# ESP32-H4 register map
Vendor: ESPRESSIF SYSTEMS (SHANGHAI) CO., LTD.; Series: ESP32 H-Series; File version: 1
CPU: RV32IMAC r0p0, little endian, no MPU, no FPU, 0 interrupt priority bits
Address unit: 32 bits
Registers are 32-bit, read-write, reset 0x0 unless marked. A register's access mark holds for its fields unless they carry their own. Offsets are from the block's base; [hi:lo] are bit positions; {n}, {i} and the like mark numbered series; <NAME> marks a mode.

## USB0 (part 3 of 4) — USB OTG (On-The-Go)
Base 0x60040000
Same registers: USB1 0x6007F000
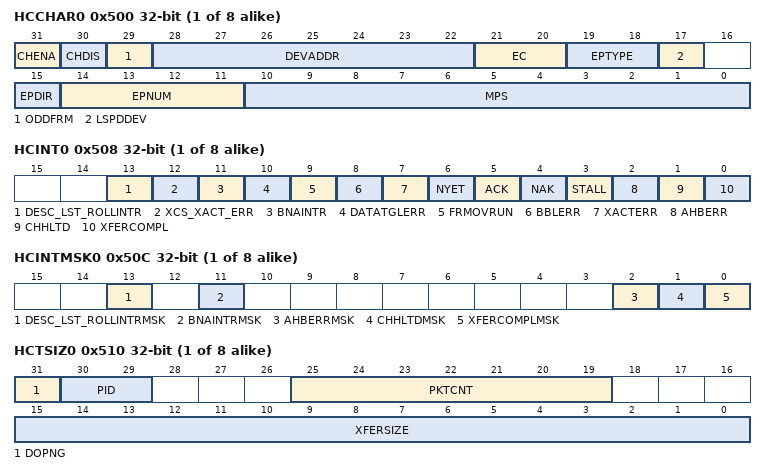
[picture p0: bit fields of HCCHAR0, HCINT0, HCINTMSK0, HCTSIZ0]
{0x500+0x20*i} HCCHAR{i} (i=0..7) — Host Channel {i} Characteristics Register
  [31] CHENA — Channel Enable (ChEna) When Scatter/Gather mode is enabled - 1'b0: Indicates that the descriptor structure is not yet ready. - 1'b1: Indicates that the descriptor structure and data buffer with data is setup and this channel can access the descriptor. When Scatter/Gather mode is disabled This field is set by the application and cleared by the OTG host. - 1'b0: Channel disabled - 1'b1: Channel enabled
  [30] CHDIS — Channel Disable (ChDis) The application sets this bit to stop transmitting/receiving data on a channel, even before the transfer for that channel is complete. The application must wait for the Channel Disabled interrupt before treating the channel as disabled.
  [29] ODDFRM — Odd Frame (OddFrm) This field is set (reset) by the application to indicate that the OTG host must perform a transfer in an odd (micro)Frame. This field is applicable for only periodic (isochronous and interrupt) transactions. - 1'b0: Even (micro)Frame - 1'b1: Odd (micro)Frame
  [28:22] DEVADDR — Device Address (DevAddr) This field selects the specific device serving as the data source or sink.
  [21:20] EC — Multi Count (MC) / Error Count (EC) When the Split Enable bit of the Host Channel-n Split Control register (HCSPLTn.SpltEna) is reset (1'b0), this field indicates to the host the number of transactions that must be executed per microframe for this periodic endpoint. For non periodic transfers, this field is used only in DMA mode, and specifies the number packets to be fetched for this channel before the internal DMA engine changes arbitration. - 2'b00: Reserved This field yields undefined results. - 2'b01: 1 transaction - 2'b10: 2 transactions to be issued for this endpoint per microframe - 2'b11: 3 transactions to be issued for this endpoint per microframe When HCSPLTn.SpltEna is Set (1'b1), this field indicates the number of immediate retries to be performed for a periodic split transactions on transaction errors. This field must be Set to at least 2'b01.
  [19:18] EPTYPE — Endpoint Type (EPType) Indicates the transfer type selected. - 2'b00: Control - 2'b01: Isochronous - 2'b10: Bulk - 2'b11: Interrupt
  [17] LSPDDEV — Low-Speed Device (LSpdDev) This field is Set by the application to indicate that this channel is communicating to a low-speed device. The application must program this bit when a low speed device is connected to the host through an FS HUB. The DWC_otg Host core uses this field to drive the XCVR_SELECT signal to 2'b11 while communicating to the LS Device through the FS hub. Note: In a peer to peer setup, the DWC_otg Host core ignores this bit even if it is set by the application software.
  [15] EPDIR — Endpoint Direction (EPDir) Indicates whether the transaction is IN or OUT. - 1'b0: OUT - 1'b1: IN
  [14:11] EPNUM — Endpoint Number (EPNum) Indicates the endpoint number on the device serving as the data source or sink.
  [10:0] MPS — Maximum Packet Size (MPS) Indicates the maximum packet size of the associated endpoint.
{0x508+0x20*i} HCINT{i} (i=0..7) — Host Channel $i Interrupt Register This register indicates the status of a channel with respect to USB- and AHB-related events. It is shown in the Interrupt Hierarchy figure in the databook. The application must read this register when the Host Channels Interrupt bit of the Core Interrupt register (GINTSTS.HChInt) is set. Before the application can read this register, it must first read the Host All Channels Interrupt (HAINT) register to get the exact channel number for the Host Channel-n Interrupt register. The application must clear the appropriate bit in this register to clear the corresponding bits in the HAINT and GINTSTS registers.
  [13] DESC_LST_ROLLINTR — Descriptor rollover interrupt (DESC_LST_ROLLIntr) This bit is valid only when Scatter/Gather DMA mode is enabled. The core sets this bit when the corresponding channel's descriptor list rolls over. For non Scatter/Gather DMA mode, this bit is reserved.
  [12] XCS_XACT_ERR — Excessive Transaction Error (XCS_XACT_ERR) This bit is valid only when Scatter/Gather DMA mode is enabled. The core sets this bit when 3 consecutive transaction errors occurred on the USB bus. XCS_XACT_ERR will not be generated for Isochronous channels. For non Scatter/Gather DMA mode, this bit is reserved.
  [11] BNAINTR — BNA (Buffer Not Available) Interrupt (BNAIntr) This bit is valid only when Scatter/Gather DMA mode is enabled. The core generates this interrupt when the descriptor accessed is not ready for the Core to process. BNA will not be generated for Isochronous channels. For non Scatter/Gather DMA mode, this bit is reserved.
  [10] DATATGLERR — Data Toggle Error (DataTglErr).This bit can be set only by the core and the application should write 1 to clear it.In Scatter/Gather DMA mode, the interrupt due to this bit is masked in the core.
  [9] FRMOVRUN — Frame Overrun (FrmOvrun). In Scatter/Gather DMA mode, the interrupt due to this bit is masked in the core. This bit can be set only by the core and the application should write 1 to clear it.
  [8] BBLERR — Babble Error (BblErr) In Scatter/Gather DMA mode, the interrupt due to this bit is masked in the core. This bit can be set only by the core and the application should write 1 to clear it.
  [7] XACTERR — Transaction Error (XactErr) Indicates one of the following errors occurred on the USB. - CRC check failure - Timeout - Bit stuff error - False EOP In Scatter/Gather DMA mode, the interrupt due to this bit is masked in the core.This bit can be set only by the core and the application should write 1 to clear it.
  [6] NYET — NYET Response Received Interrupt (NYET) In Scatter/Gather DMA mode, the interrupt due to this bit is masked in the core.This bit can be set only by the core and the application should write 1 to clear it.
  [5] ACK — ACK Response Received/Transmitted Interrupt (ACK) In Scatter/Gather DMA mode, the interrupt due to this bit is masked in the core.This bit can be set only by the core and the application should write 1 to clear it.
  [4] NAK — NAK Response Received Interrupt (NAK) In Scatter/Gather DMA mode, the interrupt due to this bit is masked in the core.This bit can be set only by the core and the application should write 1 to clear it.
  [3] STALL — STALL Response Received Interrupt (STALL) In Scatter/Gather DMA mode, the interrupt due to this bit is masked in the core.This bit can be set only by the core and the application should write 1 to clear it.
  [2] AHBERR — AHB Error (AHBErr) This is generated only in Internal DMA mode when there is an AHB error during AHB read/write. The application can read the corresponding channel's DMA address register to get the error address.
  [1] CHHLTD — Channel Halted (ChHltd) In non Scatter/Gather DMA mode, it indicates the transfer completed abnormally either because of any USB transaction error or in response to disable request by the application or because of a completed transfer. In Scatter/gather DMA mode, this indicates that transfer completed due to any of the following - EOL being set in descriptor - AHB error - Excessive transaction errors - Babble - Stall
  [0] XFERCOMPL — Transfer Completed (XferCompl) Transfer completed normally without any errors.This bit can be set only by the core and the application should write 1 to clear it. - For Scatter/Gather DMA mode, it indicates that current descriptor processing got completed with IOC bit set in its descriptor. - In non Scatter/Gather DMA mode, it indicates that Transfer completed normally without any errors.
{0x50C+0x20*i} HCINTMSK{i} (i=0..7) — Host Channel $i Interrupt Mask Register This register reflects the mask for each channel status described in the previous section.
  [13] DESC_LST_ROLLINTRMSK — Descriptor List rollover interrupt Mask register(DESC_LST_ROLLIntrMsk) This bit is valid only when Scatter/Gather DMA mode is enabled.
  [11] BNAINTRMSK — BNA (Buffer Not Available) Interrupt mask register (BNAIntrMsk) This bit is valid only when Scatter/Gather DMA mode is enabled.
  [2] AHBERRMSK — AHB Error Mask (AHBErrMsk) In scatter/gather DMA mode for host, interrupts will not be generated due to the corresponding bits set in HCINTn.
  [1] CHHLTDMSK — Channel Halted Mask (ChHltdMsk)
  [0] XFERCOMPLMSK — Transfer Completed Mask (XferComplMsk)
{0x510+0x20*i} HCTSIZ{i} (i=0..7) — Host Channel {i} Transfer Size Register
  [31] DOPNG — Do Ping (DoPng) This bit is used only for OUT transfers. Setting this field to 1 directs the host to do PING protocol. Note: Do not set this bit for IN transfers. If this bit is set for for IN transfers it disables the channel.
  [30:29] PID — PID (Pid) The application programs this field with the type of PID to use for the initial transaction. The host maintains this field for the rest of the transfer. - 2'b00: DATA0 - 2'b01: DATA2 - 2'b10: DATA1 - 2'b11: MDATA (non-control)/SETUP (control)
  [25:19] PKTCNT — Packet Count (PktCnt) This field is programmed by the application with the expected number of packets to be transmitted (OUT) or received (IN). The host decrements this count on every successful transmission or reception of an OUT/IN packet. Once this count reaches zero, the application is interrupted to indicate normal completion. The width of this counter is specified as Width of Packet Counters during coreConsultant configuration (parameter OTG_PACKET_COUNT_WIDTH).
  [15:0] XFERSIZE — Transfer Size (XferSize) For an OUT, this field is the number of data bytes the host sends during the transfer. For an IN, this field is the buffer size that the application has Reserved for the transfer. The application is expected to program this field as an integer multiple of the maximum packet size for IN transactions (periodic and non-periodic). The width of this counter is specified as Width of Transfer Size Counters during coreConsultant configuration (parameter OTG_TRANS_COUNT_WIDTH).
{0x514+0x20*i} HCDMA{i} (i=0..7) — Host Channel $i DMA Address Register This register is used by the OTG host in the internal DMA mode to maintain the current buffer pointer for IN/OUT transactions. The starting DMA address must be DWORD-aligned.
  [31:0] DMAADDR — In Buffer DMA Mode: [31:0]: DMA Address (DMAAddr) This field holds the start address in the external memory from which the data for the endpoint must be fetched or to which it must be stored. This register is incremented on every AHB transaction. Reset: X if not programmed as the register is in SPRAM. In Scatter-Gather DMA (DescDMA) Mode for Non-Isochronous: [31:9]: DMA Address (DMAAddr) The start address must be 512-bytes aligned. This field holds the start address of the 512 bytes page. The first descriptor in the list should be located in this address. The first descriptor may be or may not be ready. The core starts processing the list from the CTD value. [8:3]: Current Transfer Desc(CTD) This value is in terms of number of descriptors. The values can be from 0 to 63. - 0 - 1 descriptor. - 63 - 64 descriptors. This field indicates the current descriptor processed in the list. This field is updated both by application and the core. For example, if the application enables the channel after programming CTD=5, then the core will start processing the sixth descriptor. The address is obtained by adding a value of (8bytes*5=) 40(decimal) to DMAAddr. Reset: 6'h0 [2:0]: Reserved In Scatter-Gather DMA (DescDMA) Mode for Isochronous: [31:N]: DMA Address (DMAAddr) The start address must be 512-bytes aligned. This field holds the address of the 2*(nTD+1) bytes of locations in which the isochronous descriptors are present where N is based on nTD as follows: - [31:N]: Base Address - [N-1:3]: Offset - [2:0]: 000 For HS ISOC, if nTD is, - 7, N=6 - 15, N=7 - 31, N=8 - 63, N=9 - 127, N=10 - 255, N=11 For FS ISOC, if nTD is, - 1, N=4 - 3, N=5 - 7, N=6 - 15, N=7 - 31, N=8 - 63, N=9 [N-1:3]: Current Transfer Desc(CTD) CTD for isochronous is based on the current frame/(micro)frame value. Need to be set to zero by application. Reset: (N+1:3)'h0 [2:0]: Reserved
{0x51C+0x20*i} HCDMAB{i} ro (i=0..7) — Host Channel $i DMA Buffer Address Register This register is present only in case of Scatter/Gather DMA. It is implemented in RAM instead of flop-based implementation. This register holds the current buffer address.
  [31:0] HCDMAB — Holds the current buffer address. This register is updated as and when the data transfer for the corresponding end point is in progress. This register is present only in Scatter/Gather DMA mode. Otherwise this field is reserved.
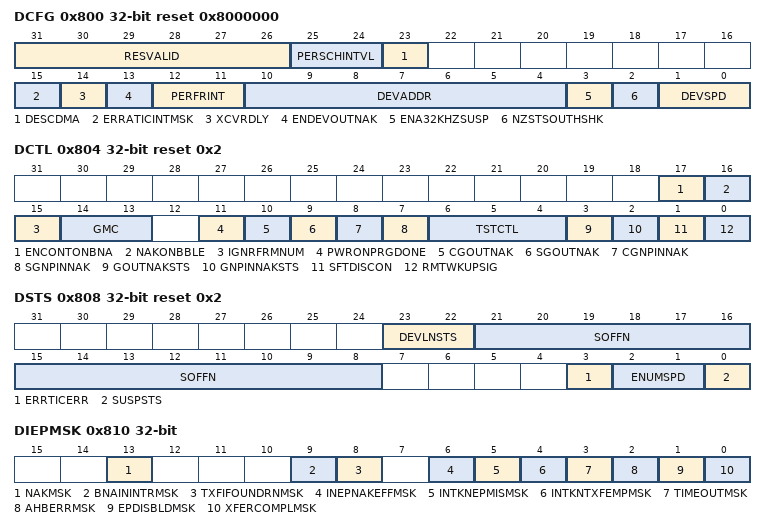
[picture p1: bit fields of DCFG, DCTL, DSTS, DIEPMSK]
0x800 DCFG reset 0x8000000 — Device Configuration Register This register configures the core in Device mode after power-on or after certain control commands or enumeration. Do not make changes to this register after initial programming.
  [31:26] RESVALID — Resume Validation Period (ResValid) This field is effective only when DCFG.Ena32KHzSusp is set. It controls the resume period when the core resumes from suspend. The core counts for ResValid number of clock cycles to detect a valid resume when this bit is set
  [25:24] PERSCHINTVL — Periodic Scheduling Interval (PerSchIntvl) PerSchIntvl must be programmed for Scatter/Gather DMA mode. This field specifies the amount of time the Internal DMA engine must allocate for fetching periodic IN endpoint data. Based on the number of periodic endpoints, this value must be specified as 25,50 or 75% of (micro)Frame. - When any periodic endpoints are active, the internal DMA engine allocates the specified amount of time in fetching periodic IN endpoint data . - When no periodic endpoints are active, Then the internal DMA engine services non-periodic endpoints, ignoring this field. - After the specified time within a (micro)Frame, the DMA switches to fetching for non-periodic endpoints. -- 2'b00: 25% of (micro)Frame. -- 2'b01: 50% of (micro)Frame. -- 2'b10: 75% of (micro)Frame. -- 2'b11: Reserved. Reset: 2'b00
  [23] DESCDMA — Enable Scatter/gather DMA in device mode (DescDMA). When the Scatter/Gather DMA option selected during configuration of the RTL, the application can Set this bit during initialization to enable the Scatter/Gather DMA operation. Note: This bit must be modified only once after a reset. The following combinations are available for programming: - GAHBCFG.DMAEn=0,DCFG.DescDMA=0 => Slave mode - GAHBCFG.DMAEn=0,DCFG.DescDMA=1 => Invalid - GAHBCFG.DMAEn=1,DCFG.DescDMA=0 => Buffered DMA mode - GAHBCFG.DMAEn=1,DCFG.DescDMA=1 => Scatter/Gather DMA mode
  [15] ERRATICINTMSK — Erratic Error Interrupt Mask
  [14] XCVRDLY — XCVRDLY Enables or disables delay between xcvr_sel and txvalid during device chirp
  [13] ENDEVOUTNAK — Enable Device OUT NAK (EnDevOutNak) This bit enables setting NAK for Bulk OUT endpoints after the transfer is completed for Device mode Descriptor DMA - 1'b0 : The core does not set NAK after Bulk OUT transfer complete - 1'b1 : The core sets NAK after Bulk OUT transfer complete It bit is one time programmable after reset like any other DCFG register bits.
  [12:11] PERFRINT — Periodic Frame Interval (PerFrInt) Indicates the time within a (micro)Frame at which the application must be notified using the End Of Periodic Frame Interrupt. This can be used to determine If all the isochronous traffic for that (micro)Frame is complete. - 2'b00: 80% of the (micro)Frame interval - 2'b01: 85% of the (micro)Frame interval - 2'b10: 90% of the (micro)Frame interval - 2'b11: 95% of the (micro)Frame interval
  [10:4] DEVADDR — Device Address (DevAddr) The application must program this field after every SetAddress control command.
  [3] ENA32KHZSUSP — Enable 32 KHz Suspend mode (Ena32KHzSusp) This bit can be set only if FS PHY interface is selected. Otherwise, this bit needs to be set to zero. If FS PHY interface is chosen and this bit is set, the PHY clock during Suspend must be switched from 48 MHz to 32 KHz.
  [2] NZSTSOUTHSHK — Non-Zero-Length Status OUT Handshake (NZStsOUTHShk) The application can use this field to select the handshake the core sends on receiving a nonzero-length data packet during the OUT transaction of a control transfer's Status stage. - 1'b1: Send a STALL handshake on a nonzero-length status OUT transaction and do not send the received OUT packet to the application. - 1'b0: Send the received OUT packet to the application (zerolength or nonzero-length) and send a handshake based on the NAK and STALL bits for the endpoint in the Device Endpoint Control register.
  [1:0] DEVSPD — Device Speed (DevSpd) Indicates the speed at which the application requires the core to enumerate, or the maximum speed the application can support. However, the actual bus speed is determined only after the connect sequence is completed, and is based on the speed of the USB host to which the core is connected.
0x804 DCTL access per field reset 0x2 — Device Control Register
  [17] ENCONTONBNA rw — Enable Continue on BNA (EnContOnBNA) This bit enables the core to continue on BNA for Bulk OUT endpoints. With this feature enabled, when a Bulk OUT or INTR OUT endpoint receives a BNA interrupt the core starts processing the descriptor that caused the BNA interrupt after the endpoint re-enables the endpoint. - 1'b0: After receiving BNA interrupt,the core disables the endpoint. When the endpoint is re-enabled by the application,the core starts processing from the DOEPDMA descriptor. - 1'b1: After receiving BNA interrupt, the core disables the endpoint. When the endpoint is re-enabled by the application, the core starts processing from the descriptor that received the BNA interrupt. This bit is valid only when OTG_EN_DESC_DMA == 1'b1. It is a one-time programmable after reset bit like any other DCTL register bits.
  [16] NAKONBBLE rw — NAK on Babble Error (NakOnBble) Set NAK automatically on babble (NakOnBble). The core sets NAK automatically for the endpoint on which babble is received.
  [15] IGNRFRMNUM rw — Ignore Frame Number Feature for Isochronous Endpoints (IgnrFrmNum) This field is also used to control the Periodic Transfer Interrupt (PTI) feature. Note: Do not program IgnrFrmNum bit to 1'b1 when the core is operating in threshold mode. Slave Mode (GAHBCFG.DMAEn=0): This bit is not valid in Slave mode and should not be programmed to 1. Scatter/Gather DMA Mode (GAHBCFG.DMAEn=1,DCFG.DescDMA=1): Note: When Scatter/Gather DMA mode is enabled this feature is not applicable to High Speed, High bandwidth transfers. When this bit is enabled, there must be only one packet per descriptor. - 0: The core transmits the packets only in the frame number in which they are intended to be transmitted. - 1: The core ignores the frame number, sending packets immediately as the packets are ready. In Scatter/Gather DMA mode, if this bit is enabled, the packets are not flushed when a ISOC IN token is received for an elapsed frame. Non-Scatter/Gather DMA Mode, that is, Buffer DMA Mode (GAHBCFG.DMAEn=1,DCFG.DescDMA=0): When Scatter/Gather DMA mode is disabled, this field is used by the application to enable Periodic Transfer Interrupt (PTI) Mode. The application can program Periodic Endpoint transfers for multiple (micro)Frames. - 0: Periodic Transfer Interrupt feature is disabled, application needs to program transfers for periodic endpoints every (micro)Frame - 1: Periodic Transfer Interrupt feature is enabled, application can program transfers for multiple (micro)Frames for periodic endpoints. In the PTI mode, the application will receive Transfer Complete Interrupt after transfers for multiple (micro)Frames are completed.
  [14:13] GMC rw — Global Multi Count (GMC) GMC must be programmed only once after initialization. Applicable only for Scatter/Gather DMA mode. This indicates the number of packets to be serviced for that end point before moving to the next end point. It is only for non-periodic endpoints. - 2'b00: Invalid. - 2'b01: 1 packet. - 2'b10: 2 packets. - 2'b11: 3 packets. The value of this field automatically changes to 2'h1 when DCFG.DescDMA is set to 1. When Scatter/Gather DMA mode is disabled, this field is reserved. and reads 2'b00.
  [11] PWRONPRGDONE rw — Power-On Programming Done (PWROnPrgDone) The application uses this bit to indicate that register programming is completed after a wake-up from Power Down mode.
  [10] CGOUTNAK rw — Clear Global OUT NAK (CGOUTNak) A write to this field clears the Global OUT NAK.
  [9] SGOUTNAK rw — Set Global OUT NAK (SGOUTNak) A write to this field sets the Global OUT NAK. The application uses this bit to send a NAK handshake on all OUT endpoints. The application must set the this bit only after making sure that the Global OUT NAK Effective bit in the Core Interrupt Register (GINTSTS.GOUTNakEff) is cleared.
  [8] CGNPINNAK rw — Clear Global Non-periodic IN NAK (CGNPInNak) A write to this field clears the Global Non-periodic IN NAK.
  [7] SGNPINNAK rw — Set Global Non-periodic IN NAK (SGNPInNak) A write to this field sets the Global Non-periodic IN NAK.The application uses this bit to send a NAK handshake on all non-periodic IN endpoints. The core can also Set this bit when a timeout condition is detected on a non-periodic endpoint in shared FIFO operation. The application must Set this bit only after making sure that the Global IN NAK Effective bit in the Core Interrupt Register (GINTSTS.GINNakEff) is cleared
  [6:4] TSTCTL rw — Test Control (TstCtl) - 3'b000: Test mode disabled - 3'b001: Test_J mode - 3'b010: Test_K mode - 3'b011: Test_SE0_NAK mode - 3'b100: Test_Packet mode - 3'b101: Test_Force_Enable - Others: Reserved
  [3] GOUTNAKSTS ro — Global OUT NAK Status (GOUTNakSts) - 1'b0: A handshake is sent based on the FIFO Status and the NAK and STALL bit settings. - 1'b1: No data is written to the RxFIFO, irrespective of space availability. Sends a NAK handshake on all packets, except on SETUP transactions. All isochronous OUT packets are dropped.
  [2] GNPINNAKSTS ro — Global Non-periodic IN NAK Status (GNPINNakSts) - 1'b0: A handshake is sent out based on the data availability in the transmit FIFO. - 1'b1: A NAK handshake is sent out on all non-periodic IN endpoints, irrespective of the data availability in the transmit FIFO.
  [1] SFTDISCON rw — Soft Disconnect (SftDiscon) The application uses this bit to signal the controller to do a soft disconnect. As long as this bit is Set, the host does not see that the device is connected, and the device does not receive signals on the USB. The core stays in the disconnected state until the application clears this bit. - 1'b0: Normal operation. When this bit is cleared after a soft disconnect, the core drives the phy_opmode_o signal on the UTMI+ to 2'b00, which generates a device connect event to the USB host. When the device is reconnected, the USB host restarts device enumeration. - 1'b1: The core drives the phy_opmode_o signal on the UTMI+ to 2'b01, which generates a device disconnect event to the USB host. The following is the minimum duration under various conditions for which this bit must be set for the USB host to detect a device disconnect. To accommodate clock jitter, it is recommended that the application adds some extra delay to the specified minimum duration. For high speed, if the device state is, - Suspended, the minimum duration is 1ms + 2.5us - Idle, the minimum duration is 3ms + 2.5us - Not Idle or Suspended (performing transactions), the minimum duration 125 us For full speed/low speed, if the device state is, - Suspended, the minimum duration is 1ms + 2.5us - Idle, the minimum duration is 2.5us - Not Idle or Suspended (performing transactions), the minimum duration 125 us Note: - This bit can be also used for ULPI/FS Serial interfaces. - This bit is not impacted by a soft reset.
  [0] RMTWKUPSIG rw — Remote Wakeup Signaling (RmtWkUpSig) When the application sets this bit, the core initiates remote signaling to wake up the USB host. The application must Set this bit to instruct the core to exit the Suspend state. As specified in the USB 2.0 specification, the application must clear this bit 1-15 ms after setting it. If LPM is enabled and the core is in the L1 (Sleep) state, when the application sets this bit, the core initiates L1 remote signaling to wake up the USB host. The application must set this bit to instruct the core to exit the Sleep state. As specified in the LPM specification, the hardware automatically clears this bit 50 microseconds (TL1DevDrvResume) after being set by the application. The application must not set this bit when GLPMCFG bRemoteWake from the previous LPM transaction is zero.
0x808 DSTS ro reset 0x2 — Device Status Register This register indicates the status of the core with respect to USB-related events. It must be read on interrupts from Device All Interrupts (DAINT) register.
  [23:22] DEVLNSTS — Device Line Status (DevLnSts) Indicates the current logic level USB data lines - DevLnSts[1]: Logic level of D+ - DevLnSts[0]: Logic level of D-
  [21:8] SOFFN — Frame or Microframe Number of the Received SOF (SOFFN) When the core is operating at high speed, this field contains a microframe number. When the core is operating at full or low speed, this field contains a Frame number. Note: This register may return a non-zero value if read immediately after power-on reset. In case the register bit reads non-zero immediately after power-on reset, it does not indicate that SOF has been received from the host. The read value of this interrupt is valid only after a valid connection between host and device is established.
  [3] ERRTICERR — Erratic Error (ErrticErr) The core sets this bit to report any erratic errors (phy_rxvalid_i/phy_rxvldh_i or phy_rxactive_i is asserted for at least 2 ms, due to PHY error) seen on the UTMI+. Due to erratic errors, the DWC_otg core goes into Suspended state and an interrupt is generated to the application with Early Suspend bit of the Core Interrupt register (GINTSTS.ErlySusp). If the early suspend is asserted due to an erratic error, the application can only perform a soft disconnect recover.
  [2:1] ENUMSPD — Enumerated Speed (EnumSpd) Indicates the speed at which the controller has come up after speed detection through a connect or reset sequence. - 2'b00: High speed (PHY clock is running at 30 or 60 MHz) - 2'b01: Full speed (PHY clock is running at 30 or 60 MHz) - 2'b10: Low speed (PHY clock is running at 6 MHz) - 2'b11: Full speed (PHY clock is running at 48 MHz) Low speed is not supported for devices using a UTMI+ PHY.
  [0] SUSPSTS — Suspend Status (SuspSts) In Device mode, this bit is set as long as a Suspend condition is detected on the USB. The core enters the Suspend state when there is no activity on the phy_line_state_i signal for an extended period of time. The core comes out of the suspend under the following conditions : - If there is any activity on the phy_line_state_i signal, or - If the application writes to the Remote Wakeup Signaling bit in the Device Control register (DCTL.RmtWkUpSig). When the core comes out of the suspend, this bit is set to 1'b0.
0x810 DIEPMSK — Device IN Endpoint Common Interrupt Mask Register This register works with each of the Device IN Endpoint Interrupt (DIEPINTn) registers for all endpoints to generate an interrupt per IN endpoint. The IN endpoint interrupt for a specific status in the DIEPINTn register can be masked by writing to the corresponding bit in this register. Status bits are masked by default.
  [13] NAKMSK — NAK interrupt Mask (NAKMsk)
  [9] BNAININTRMSK — BNA interrupt Mask (BNAInIntrMsk)
  [8] TXFIFOUNDRNMSK — Fifo Underrun Mask (TxfifoUndrnMsk)
  [6] INEPNAKEFFMSK — IN Endpoint NAK Effective Mask (INEPNakEffMsk)
  [5] INTKNEPMISMSK — IN Token received with EP Mismatch Mask (INTknEPMisMsk)
  [4] INTKNTXFEMPMSK — IN Token Received When TxFIFO Empty Mask (INTknTXFEmpMsk)
  [3] TIMEOUTMSK — Timeout Condition Mask (TimeOUTMsk) (Non-isochronous endpoints)
  [2] AHBERRMSK — AHB Error Mask (AHBErrMsk)
  [1] EPDISBLDMSK — Endpoint Disabled Interrupt Mask (EPDisbldMsk)
  [0] XFERCOMPLMSK — Transfer Completed Interrupt Mask (XferComplMsk)
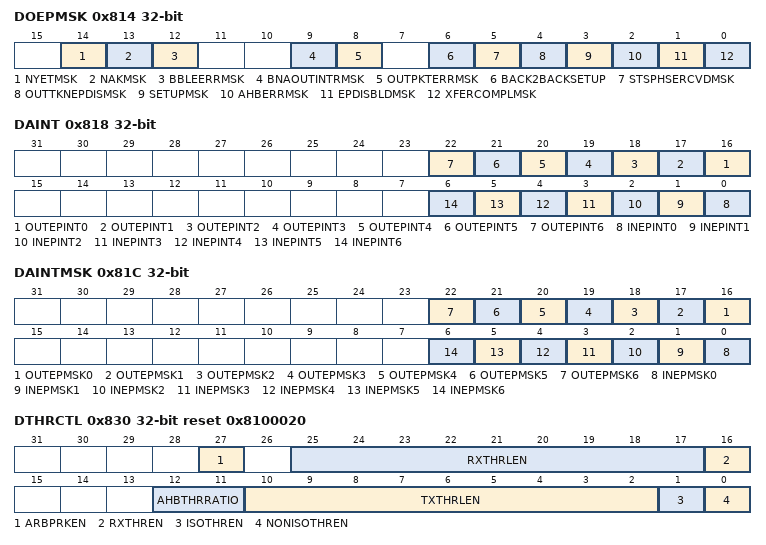
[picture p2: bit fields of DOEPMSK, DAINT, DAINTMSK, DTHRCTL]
0x814 DOEPMSK — Device OUT Endpoint Common Interrupt Mask Register This register works with each of the Device OUT Endpoint Interrupt (DOEPINTn) registers for all endpoints to generate an interrupt per OUT endpoint. The OUT endpoint interrupt for a specific status in the DOEPINTn register can be masked by writing into the corresponding bit in this register. Status bits are masked by default.
  [14] NYETMSK — NYET interrupt Mask (NYETMsk)
  [13] NAKMSK — NAK interrupt Mask (NAKMsk)
  [12] BBLEERRMSK — Babble Error interrupt Mask (BbleErrMsk)
  [9] BNAOUTINTRMSK — BNA interrupt Mask (BnaOutIntrMsk)
  [8] OUTPKTERRMSK — OUT Packet Error Mask (OutPktErrMsk)
  [6] BACK2BACKSETUP — Back-to-Back SETUP Packets Received Mask (Back2BackSETup) Applies to control OUT endpoints only.
  [5] STSPHSERCVDMSK — Status Phase Received Mask (StsPhseRcvdMsk) Applies to control OUT endpoints only.
  [4] OUTTKNEPDISMSK — OUT Token Received when Endpoint Disabled Mask (OUTTknEPdisMsk) Applies to control OUT endpoints only.
  [3] SETUPMSK — SETUP Phase Done Mask (SetUPMsk) Applies to control endpoints only.
  [2] AHBERRMSK — AHB Error (AHBErrMsk)
  [1] EPDISBLDMSK — Endpoint Disabled Interrupt Mask (EPDisbldMsk)
  [0] XFERCOMPLMSK — Transfer Completed Interrupt Mask (XferComplMsk)
0x818 DAINT ro — Device All Endpoints Interrupt Register When a significant event occurs on an endpoint, a Device All Endpoints Interrupt register interrupts the application using the Device OUT Endpoints Interrupt bit or Device IN Endpoints Interrupt bit of the Core Interrupt register (GINTSTS.OEPInt or GINTSTS.IEPInt, respectively). This is shown in Figure 5-2. There is one interrupt bit per endpoint, up to a maximum of 16 bits for OUT endpoints and 16 bits for IN endpoints. For a bidirectional endpoint, the corresponding IN and OUT interrupt bits are used. Bits in this register are set and cleared when the application sets and clears bits in the corresponding Device Endpoint-n Interrupt register (DIEPINTn/DOEPINTn).
  [n+16] OUTEPINT{n} (n=0..6) — OUT Endpoint {n} Interrupt Bit
  [n] INEPINT{n} (n=0..6) — IN Endpoint {n} Interrupt Bit
0x81C DAINTMSK — Device All Endpoints Interrupt Mask Register The Device Endpoint Interrupt Mask register works with the Device Endpoint Interrupt register to interrupt the application when an event occurs on a device endpoint. However, the Device All Endpoints Interrupt (DAINT) register bit corresponding to that interrupt is still set.
  [n+16] OUTEPMSK{n} (n=0..6) — OUT Endpoint {n} Interrupt mask Bit
  [n] INEPMSK{n} (n=0..6) — IN Endpoint {n} Interrupt mask Bit
0x828 DVBUSDIS reset 0x17D7 — Device VBUS Discharge Time Register This register specifies the VBUS discharge time after VBUS pulsing during SRP.
  [15:0] DVBUSDIS — Device VBUS Discharge Time (DVBUSDis) Specifies the VBUS discharge time after VBUS pulsing during SRP. This value equals (VBUS discharge time in PHY clocks) / 1, 024. The value you use depends whether the PHY is operating at 30MHz (16-bit data width) or 60 MHz (8-bit data width). Depending on your VBUS load, this value can need adjustment.
0x82C DVBUSPULSE reset 0x5B8 — Device VBUS Pulsing Time Register
  [11:0] DVBUSPULSE — Device VBUS Pulsing Time (DVBUSPulse) Specifies the VBUS pulsing time during SRP. This value equals (VBUS pulsing time in PHY clocks) / 1, 024 The value you use depends whether the PHY is operating at 30MHz (16-bit data width) or 60 MHz (8-bit data width).
0x830 DTHRCTL reset 0x8100020 — Device Threshold Control Register
  [27] ARBPRKEN — Arbiter Parking Enable (ArbPrkEn) This bit controls internal DMA arbiter parking for IN endpoints. If thresholding is enabled and this bit is set to one, then the arbiter parks on the IN endpoint for which there is a token received on the USB. This is done to avoid getting into underrun conditions. By default, arbiter parking is enabled.
  [25:17] RXTHRLEN — Receive Threshold Length (RxThrLen) This field specifies Receive thresholding size in DWORDS. This field also specifies the amount of data received on the USB before the core can start transmitting on the AHB. The threshold length has to be at least eight DWORDS. The recommended value for ThrLen is to be the same as the programmed AHB Burst Length (GAHBCFG.HBstLen).
  [16] RXTHREN — Receive Threshold Enable (RxThrEn) When this bit is set, the core enables thresholding in the receive direction. Note: We recommends that you do not enable RxThrEn, because it may cause issues in the RxFIFO especially during error conditions such as RxError and Babble.
  [12:11] AHBTHRRATIO — AHB Threshold Ratio (AHBThrRatio) These bits define the ratio between the AHB threshold and the MAC threshold for the transmit path only. The AHB threshold always remains less than or equal to the USB threshold, because this does not increase overhead. Both the AHB and the MAC threshold must be DWORD-aligned. The application needs to program TxThrLen and the AHBThrRatio to make the AHB Threshold value DWORD aligned. If the AHB threshold value is not DWORD aligned, the core might not behave correctly. When programming the TxThrLen and AHBThrRatio, the application must ensure that the minimum AHB threshold value does not go below 8 DWORDS to meet the USB turnaround time requirements. - 2'b00: AHB threshold = MAC threshold - 2'b01: AHB threshold = MAC threshold / 2 - 2'b10: AHB threshold = MAC threshold / 4 - 2'b11: AHB threshold = MAC threshold / 8
  [10:2] TXTHRLEN — Transmit Threshold Length (TxThrLen) This field specifies Transmit thresholding size in DWORDS. This also forms the MAC threshold and specifies the amount of data in bytes to be in the corresponding endpoint transmit FIFO, before the core can start transmit on the USB. The threshold length has to be at least eight DWORDS when the value of AHBThrRatio is 2'h00. In case the AHBThrRatio is non zero the application needs to ensure that the AHB Threshold value does not go below the recommended eight DWORD. This field controls both isochronous and non-isochronous IN endpoint thresholds. The recommended value for ThrLen is to be the same as the programmed AHB Burst Length (GAHBCFG.HBstLen). Note: - When OTG_ARCHITECTURE=0, the reset value of this register field is 0. - When OTG_ARCHITECTURE=2, the reset value of this register field is 8.
  [1] ISOTHREN — ISO IN Endpoints Threshold Enable. (ISOThrEn) When this bit is Set, the core enables thresholding for isochronous IN endpoints.
  [0] NONISOTHREN — Non-ISO IN Endpoints Threshold Enable. (NonISOThrEn) When this bit is Set, the core enables thresholding for Non Isochronous IN endpoints.
0x834 DIEPEMPMSK — Device IN Endpoint FIFO Empty Interrupt Mask Register This register is valid only in Dedicated FIFO operation (OTG_EN_DED_TX_FIFO = 1). This register is used to control the IN endpoint FIFO empty interrupt generation (DIEPINTn.TxfEmp).
  [15:0] INEPTXFEMPMSK — IN EP Tx FIFO Empty Interrupt Mask Bits (InEpTxfEmpMsk) These bits acts as mask bits for DIEPINTn.TxFEmp interrupt, one bit per IN Endpoint: Bit 0 for IN EP 0, bit 15 for IN EP 15
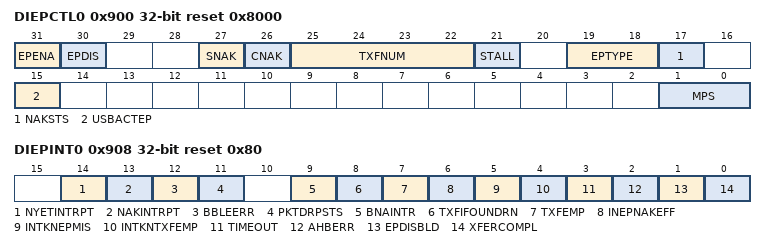
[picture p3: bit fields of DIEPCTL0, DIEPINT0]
0x900 DIEPCTL0 access per field reset 0x8000 — Device Control IN Endpoint 0 Control Register
  [31] EPENA rw — Endpoint Enable (EPEna) When Scatter/Gather DMA mode is enabled for IN endpoints, this bit indicates that the descriptor structure and data buffer with data ready to transmit is setup. When Scatter/Gather DMA mode is disabled (such as in buffer pointer based DMA mode) this bit indicates that data is ready to be transmitted on the endpoint. The core clears this bit before setting the following interrupts on this endpoint: - Endpoint Disabled - Transfer Completed
  [30] EPDIS rw — Endpoint Disable (EPDis) The application sets this bit to stop transmitting data on an endpoint, even before the transfer for that endpoint is complete. The application must wait for the Endpoint Disabled interrupt before treating the endpoint as disabled. The core clears this bit before setting the Endpoint Disabled Interrupt. The application must Set this bit only if Endpoint Enable is already set for this endpoint.
  [27] SNAK rw — Set NAK (SNAK) A write to this bit sets the NAK bit for the endpoint. Using this bit, the application can control the transmission of NAK handshakes on an endpoint. The core can also set this bit for an endpoint after a SETUP packet is received on that endpoint.
  [26] CNAK rw — Clear NAK (CNAK) A write to this bit clears the NAK bit for the endpoint.
  [25:22] TXFNUM rw — TxFIFO Number (TxFNum) - For Shared FIFO operation, this value is always set to 0, indicating that control IN endpoint 0 data is always written in the Non-Periodic Transmit FIFO. - For Dedicated FIFO operation, this value is set to the FIFO number that is assigned to IN Endpoint.
  [21] STALL rw — STALL Handshake (Stall) The application can only set this bit, and the core clears it, when a SETUP token is received for this endpoint. If a NAK bit, Global Nonperiodic IN NAK, or Global OUT NAK is set along with this bit, the STALL bit takes priority.
  [19:18] EPTYPE ro — Endpoint Type (EPType) Hardcoded to 00 for control.
  [17] NAKSTS ro — NAK Status (NAKSts) Indicates the following: - 1'b0: The core is transmitting non-NAK handshakes based on the FIFO status - 1'b1: The core is transmitting NAK handshakes on this endpoint. When this bit is set, either by the application or core, the core stops transmitting data, even If there is data available in the TxFIFO. Irrespective of this bit's setting, the core always responds to SETUP data packets with an ACK handshake.
  [15] USBACTEP ro — USB Active Endpoint (USBActEP) This bit is always SET to 1, indicating that control endpoint 0 is always active in all configurations and interfaces.
  [1:0] MPS rw — Maximum Packet Size (MPS) Applies to IN and OUT endpoints. The application must program this field with the maximum packet size for the current logical endpoint. - 2'b00: 64 bytes - 2'b01: 32 bytes - 2'b10: 16 bytes - 2'b11: 8 bytes
0x908 DIEPINT0 access per field reset 0x80 — Device IN Endpoint 0 Interrupt Register This register indicates the status of an endpoint with respect to USB- and AHB-related events. It is shown in the Interrupt Hierarchy figure in the databook. The application must read this register when the OUT Endpoints Interrupt bit or IN Endpoints Interrupt bit of the Core Interrupt register (GINTSTS.OEPInt or GINTSTS.IEPInt, respectively) is set. Before the application can read this register, it must first read the Device All Endpoints Interrupt (DAINT) register to get the exact endpoint number for the Device Endpoint-n Interrupt register. The application must clear the appropriate bit in this register to clear the corresponding bits in the DAINT and GINTSTS registers
  [14] NYETINTRPT rw — NYET Interrupt (NYETIntrpt) The core generates this interrupt when a NYET response is transmitted for a non isochronous OUT endpoint.
  [13] NAKINTRPT rw — NAK Interrupt (NAKInterrupt) The core generates this interrupt when a NAK is transmitted or received by the device. <brIn case of isochronous IN endpoints the interrupt gets generated when a zero length packet is transmitted due to un-availability of data in the TXFifo.
  [12] BBLEERR rw — NAK Interrupt (BbleErr) The core generates this interrupt when babble is received for the endpoint.
  [11] PKTDRPSTS rw — Packet Drop Status (PktDrpSts) This bit indicates to the application that an ISOC OUT packet has been dropped. This bit does not have an associated mask bit and does not generate an interrupt. Dependency: This bit is valid in non Scatter/Gather DMA mode when periodic transfer interrupt feature is selected.
  [9] BNAINTR rw — BNA (Buffer Not Available) Interrupt (BNAIntr) This bit is valid only when Scatter/Gather DMA mode is enabled. The core generates this interrupt when the descriptor accessed is not ready for the Core to process, such as Host busy or DMA done.
  [8] TXFIFOUNDRN rw — Fifo Underrun (TxfifoUndrn) Applies to IN endpoints only. The core generates this interrupt when it detects a transmit FIFO underrun condition in threshold mode for this endpoint.
  [7] TXFEMP ro — Transmit FIFO Empty (TxFEmp) This bit is valid only for IN Endpoints This interrupt is asserted when the TxFIFO for this endpoint is either half or completely empty. The half or completely empty status is determined by the TxFIFO Empty Level bit in the Core AHB Configuration register (GAHBCFG.NPTxFEmpLvl)).
  [6] INEPNAKEFF rw — IN Endpoint NAK Effective (INEPNakEff) Applies to periodic IN endpoints only. This bit can be cleared when the application clears the IN endpoint NAK by writing to DIEPCTLn.CNAK. This interrupt indicates that the core has sampled the NAK bit Set (either by the application or by the core). The interrupt indicates that the IN endpoint NAK bit Set by the application has taken effect in the core. This interrupt does not guarantee that a NAK handshake is sent on the USB. A STALL bit takes priority over a NAK bit.
  [5] INTKNEPMIS rw — IN Token Received with EP Mismatch (INTknEPMis) Applies to non-periodic IN endpoints only. Indicates that the data in the top of the non-periodic TxFIFO belongs to an endpoint other than the one for which the IN token was received. This interrupt is asserted on the endpoint for which the IN token was received.
  [4] INTKNTXFEMP rw — IN Token Received When TxFIFO is Empty (INTknTXFEmp) Applies to non-periodic IN endpoints only. Indicates that an IN token was received when the associated TxFIFO (periodic/non-periodic) was empty. This interrupt is asserted on the endpoint for which the IN token was received.
  [3] TIMEOUT rw — Timeout Condition (TimeOUT) - In shared TX FIFO mode, applies to non-isochronous IN endpoints only. - In dedicated FIFO mode, applies only to Control IN endpoints. - In Scatter/Gather DMA mode, the TimeOUT interrupt is not asserted. Indicates that the core has detected a timeout condition on the USB for the last IN token on this endpoint.
  [2] AHBERR rw — AHB Error (AHBErr) Applies to IN and OUT endpoints. This is generated only in Internal DMA mode when there is an AHB error during an AHB read/write. The application can read the corresponding endpoint DMA address register to get the error address.
  [1] EPDISBLD rw — Endpoint Disabled Interrupt (EPDisbld) Applies to IN and OUT endpoints. This bit indicates that the endpoint is disabled per the application's request.
  [0] XFERCOMPL rw — Transfer Completed Interrupt (XferCompl) Applies to IN and OUT endpoints. - When Scatter/Gather DMA mode is enabled -- For IN endpoint this field indicates that the requested data from the descriptor is moved from external system memory to internal FIFO. -- For OUT endpoint this field indicates that the requested data from the internal FIFO is moved to external system memory. This interrupt is generated only when the corresponding endpoint descriptor is closed, and the IOC bit for the corresponding descriptor is set. - When Scatter/Gather DMA mode is disabled, this field indicates that the programmed transfer is complete on the AHB as well as on the USB, for this endpoint.
